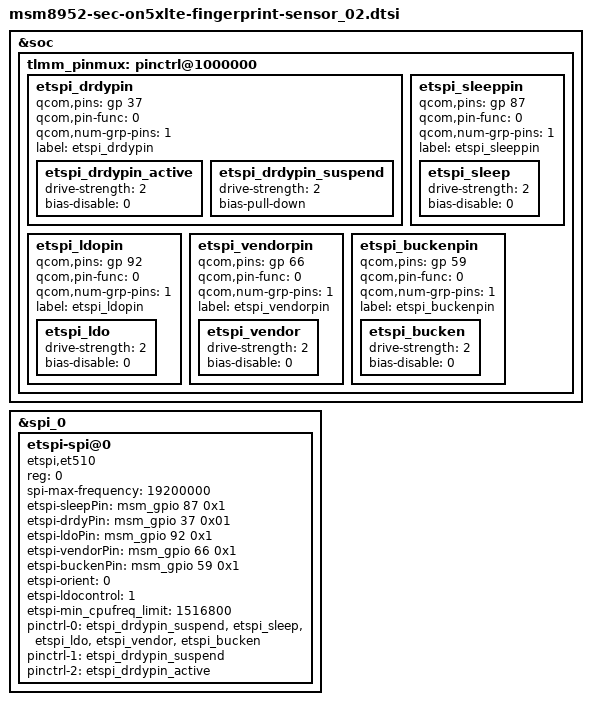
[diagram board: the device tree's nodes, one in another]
/* Copyright (c) 2013-2014, The Linux Foundation. All rights reserved.
 *
 * This program is free software; you can redistribute it and/or modify
 * it under the terms of the GNU General Public License version 2 and
 * only version 2 as published by the Free Software Foundation.
 *
 * This program is distributed in the hope that it will be useful,
 * but WITHOUT ANY WARRANTY; without even the implied warranty of
 * MERCHANTABILITY or FITNESS FOR A PARTICULAR PURPOSE.  See the
 * GNU General Public License for more details.
 */

&soc {
	tlmm_pinmux: pinctrl@1000000 {
		etspi_drdypin: etspi_drdypin {
			qcom,pins = <&gp 37>;
			qcom,pin-func = <0>;
			qcom,num-grp-pins = <1>;
			label = "etspi_drdypin";
			etspi_drdypin_active: etspi_drdypin_active {
				drive-strength = <2>;
				bias-disable = <0>;
			};
			etspi_drdypin_suspend: etspi_drdypin_suspend {
				drive-strength = <2>;
				bias-pull-down;
			};
		};

		etspi_sleeppin: etspi_sleeppin {
			qcom,pins = <&gp 87>;
			qcom,pin-func = <0>;
			qcom,num-grp-pins = <1>;
			label = "etspi_sleeppin";
			etspi_sleep: etspi_sleep {
				drive-strength = <2>;
				bias-disable = <0>;
			};
		};

		etspi_ldopin: etspi_ldopin {
			qcom,pins = <&gp 92>;
			qcom,pin-func = <0>;
			qcom,num-grp-pins = <1>;
			label = "etspi_ldopin";
			etspi_ldo: etspi_ldo {
				drive-strength = <2>;
				bias-disable = <0>;
			};
		};

		etspi_vendorpin: etspi_vendorpin {
			qcom,pins = <&gp 66>;
			qcom,pin-func = <0>;
			qcom,num-grp-pins = <1>;
			label = "etspi_vendorpin";
			etspi_vendor: etspi_vendor {
				drive-strength = <2>;
				bias-disable = <0>;
			};
		};

		etspi_buckenpin: etspi_buckenpin {
			qcom,pins = <&gp 59>;
			qcom,pin-func = <0>;
			qcom,num-grp-pins = <1>;
			label = "etspi_buckenpin";
			etspi_bucken: etspi_bucken {
				drive-strength = <2>;
				bias-disable = <0>;
			};
		};
	};
};

&spi_0 { /* BLSP1 QUP0 */
	status = "okay";

	etspi-spi@0 {
		compatible = "etspi,et510";
		reg = <0>;
		spi-max-frequency = <19200000>;
		etspi-sleepPin = <&msm_gpio 87 0x1>;
		etspi-drdyPin = <&msm_gpio 37 0x01>;
		etspi-ldoPin = <&msm_gpio 92 0x1>;
		etspi-vendorPin = <&msm_gpio 66 0x1>;
		etspi-buckenPin = <&msm_gpio 59 0x1>;
		etspi-orient = <0>;
		etspi-ldocontrol= <1>;
		etspi-min_cpufreq_limit = <1516800>;

		pinctrl-names = "default", "sleep", "idle";
		pinctrl-0 = <&etspi_drdypin_suspend &etspi_sleep &etspi_ldo &etspi_vendor &etspi_bucken>;
		pinctrl-1 = <&etspi_drdypin_suspend>;
		pinctrl-2 = <&etspi_drdypin_active>;
	};
};
